# STM32C092xx register map
File version: 1.0
Registers are 32-bit, read-write, reset 0x0 unless marked. A register's access mark holds for its fields unless they carry their own. Offsets are from the block's base; [hi:lo] are bit positions; {n}, {i} and the like mark numbered series; 'fields as' and 'values as' point back to an identical list.

## FDCAN_CONFIG — FD Controller Area Network Configuration
Base 0x40006500
0x00 CKDIV — FDCAN clock divider register
  [3:0] PDIV — Input Clock Divider

## PWR — Power Control
Base 0x40007000
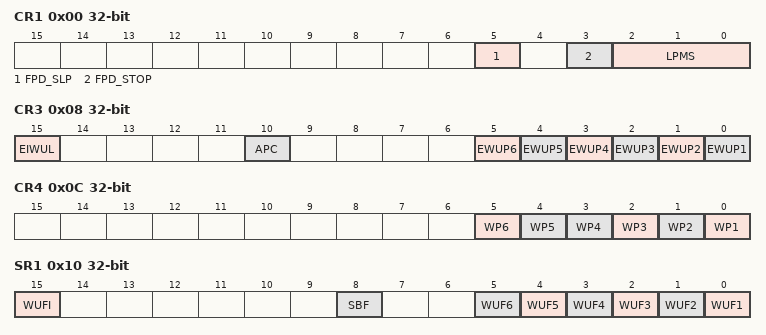
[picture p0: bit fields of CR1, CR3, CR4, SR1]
0x00 CR1 — PWR Power Control Register 1
  [5] FPD_SLP — Flash power down mode during sleep
  [3] FPD_STOP — Flash power down mode during stop
  [2:0] LPMS — Low Power Mode Selection
    0=STOP0; 3=STANDBY; 4=SHUTDOWN
0x08 CR3 — PWR Power Control Register 3
  [15] EIWUL — Enable Internal Wake-up line
  [10] APC — Apply pull-up and pull-down configuration
  [5] EWUP6 — Enable external WKUP pin 6
  [4] EWUP5 — Enable WKUP pin 5
  [3] EWUP4 — Enable external WKUP pin 4
  [2] EWUP3 — Enable external WKUP pin 3
  [1] EWUP2 — Enable external WKUP pin 2
  [0] EWUP1 — Enable external WKUP Line 1
0x0C CR4 — PWR Power Control Register 4
  [5] WP6 — Wake-Up Line 6 polarity
  [4] WP5 — Wake-Up Pin 5 polarity
  [n-1] WP{n} (n=1..4) — Wake-Up Line {n} polarity
0x10 SR1 — PWR Power Status Register 1
  [15] WUFI — Wakeup Flag Internal
  [8] SBF — Standby Flag
  [n-1] WUF{n} (n=1..6) — Wakeup Flag {n}
0x14 SR2 — PWR Power Status Register 2
  [7] FLASH_RDY — Flash Ready
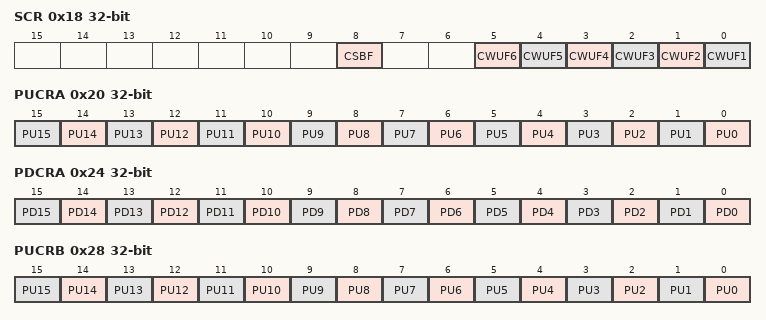
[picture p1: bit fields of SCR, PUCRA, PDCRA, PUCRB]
0x18 SCR — PWR Power Status Clear Register
  [8] CSBF — Clear Standby Flag
  [n-1] CWUF{n} (n=1..6) — Clear Wake-up Flag {n}
0x20 PUCRA — PWR Pull-Up Control Register of port A
  [n] PU{n} (n=0..15) — Pin PA{n} Pull-Up set
0x24 PDCRA — PWR Pull-Down Control Register of port A
  [n] PD{n} (n=0..15) — Pin PA{n} Pull-Down set
0x28 PUCRB — PWR Pull-Up Control Register of port B
  [n] PU{n} (n=0..15) — Pin PB{n} Pull-Up set
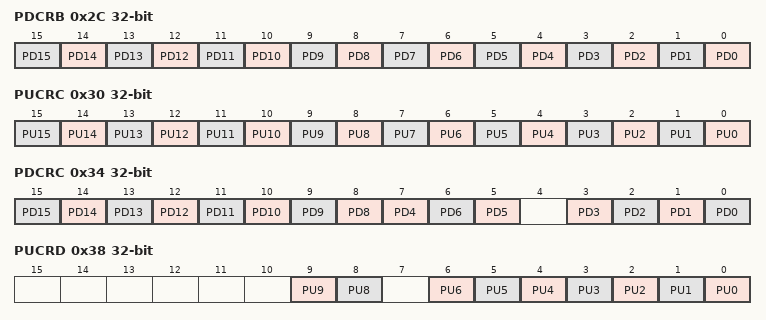
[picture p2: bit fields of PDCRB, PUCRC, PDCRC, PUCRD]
0x2C PDCRB — PWR Pull-Down Control Register of port B
  [n] PD{n} (n=0..15) — Pin PB{n} Pull-Down set
0x30 PUCRC — PWR Pull-Up Control Register of port C
  [n] PU{n} (n=0..15) — Pin PC{n} Pull-Up set
0x34 PDCRC — PWR Pull-Down Control Register of port C
  [n] PD{n} (n=8..15) — Pin PC{n} Pull-Down set
  [7] PD4 — Pin PC4 Pull-Down set
  [6] PD6 — Pin PC6 Pull-Down set
  [5] PD5 — Pin PC5 Pull-Down set
  [n] PD{n} (n=0..3) — Pin PC{n} Pull-Down set
0x38 PUCRD — PWR Pull-Up Control Register of port D
  [9] PU9 — Pin PD9 Pull-Up set
  [8] PU8 — Pin PD8 Pull-Up set
  [n] PU{n} (n=0..6) — Pin PD{n} Pull-Up set
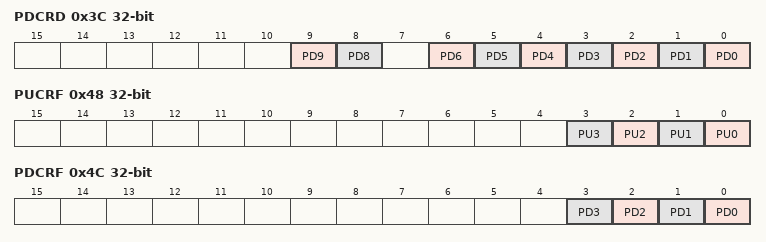
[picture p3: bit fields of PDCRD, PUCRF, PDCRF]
0x3C PDCRD — PWR Pull-Down Control Register of port D
  [9] PD9 — Pin PD9 Pull-Down set
  [8] PD8 — Pin PD8 Pull-Down set
  [n] PD{n} (n=0..6) — Pin PD{n} Pull-Down set
0x48 PUCRF — PWR Pull-Up Control Register of port F
  [n] PU{n} (n=0..3) — Pin PF{n} Pull-Up set
0x4C PDCRF — PWR Pull-Down Control Register of port F
  [n] PD{n} (n=0..3) — Pin PF{n} Pull-Down set
{0x70+4i} BKP{i}R (i=0..3) — Backup register {i}

## DBG — Debug MCU
Base 0x40015800
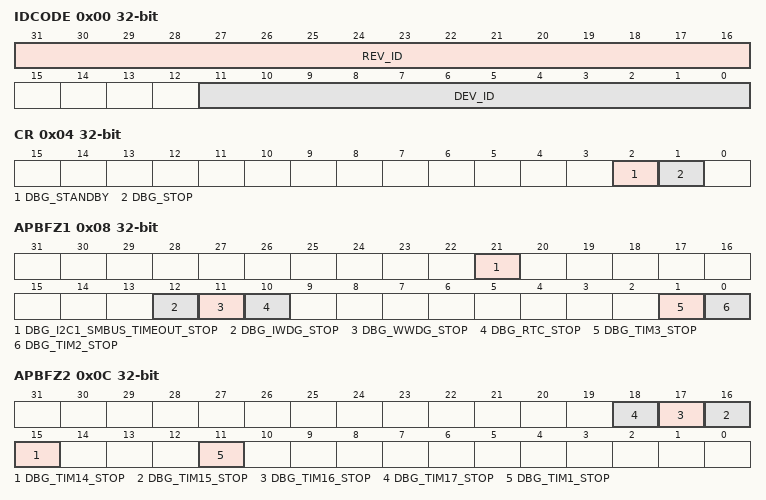
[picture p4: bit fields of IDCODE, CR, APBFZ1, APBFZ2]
0x00 IDCODE — MCU device ID code
  [31:16] REV_ID, [11:0] DEV_ID
0x04 CR — Debug configuration register
  [2] DBG_STANDBY, [1] DBG_STOP
0x08 APBFZ1 — Debug APB freeze register 1
  [21] DBG_I2C1_SMBUS_TIMEOUT_STOP, [12] DBG_IWDG_STOP, [11] DBG_WWDG_STOP, [10] DBG_RTC_STOP, [1] DBG_TIM3_STOP, [0] DBG_TIM2_STOP
0x0C APBFZ2 — Debug APB freeze register 2
  [n+1] DBG_TIM{n}_STOP (n=14..17), [11] DBG_TIM1_STOP

## DMA1
Base 0x40020000
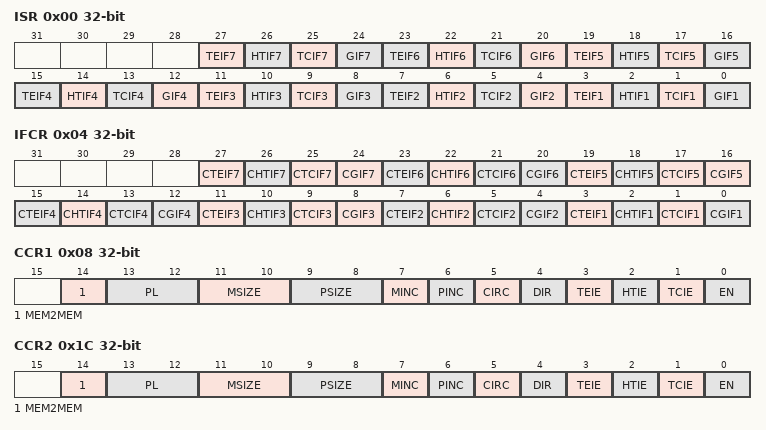
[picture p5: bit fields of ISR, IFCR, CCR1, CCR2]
0x00 ISR — DMA interrupt status register
  [4n-1] TEIF{n} (n=1..7) — Channel {n} Transfer Error flag
  [4n-2] HTIF{n} (n=1..7) — Channel {n} Half Transfer flag
  [25] TCIF7 — Channel 7Transfer Complete flag
  [4n-4] GIF{n} (n=1..7) — Channel {n} Global interrupt flag
  [4n-3] TCIF{n} (n=1..6) — Channel {n} Transfer Complete flag
0x04 IFCR — DMA interrupt flag clear register
  [4n-1] CTEIF{n} (n=1..7) — Channel {n} Transfer Error clear
  [4n-2] CHTIF{n} (n=1..7) — Channel {n} Half Transfer clear
  [4n-3] CTCIF{n} (n=1..7) — Channel {n} Transfer Complete clear
  [4n-4] CGIF{n} (n=2..7) — Channel {n} Global interrupt clear
  [0] CGIF1 — Channel 1 Global interrupt clearr
0x08 CCR1 — DMA channel x configuration register
  [14] MEM2MEM — Memory to memory mode
  [13:12] PL — PL[1:0] bits(Channel Priority level)
  [11:10] MSIZE — MSIZE[1:0] bits (Memory size)
  [9:8] PSIZE — PSIZE[1:0] bits (Peripheral size)
  [7] MINC — Memory increment mode
  [6] PINC — Peripheral increment mode
  [5] CIRC — Circular mode
  [4] DIR — Data transfer direction
  [3] TEIE — Transfer error interrupt enable
  [2] HTIE — Half Transfer interrupt enable
  [1] TCIE — Transfer complete interrupt enable
  [0] EN — Channel enable
0x0C CNDTR1 — DMA channel x number of data register
  [15:0] NDT — Number of data to Transfer
0x10 CPAR1 — DMA channel x peripheral address register
  [31:0] PA — Peripheral Address
{0x0+0x14*i} CMAR{i} (i=1..7) — DMA channel x memory address register
  [31:0] MA — Memory Address
0x1C CCR2 — DMA channel x configuration register
  fields as CCR1
0x20 CNDTR2 — DMA channel x number of data register
  [15:0] NDT — Number of data to Transfer
0x24 CPAR2 — DMA channel x peripheral address register
  [31:0] PA — Peripheral Address
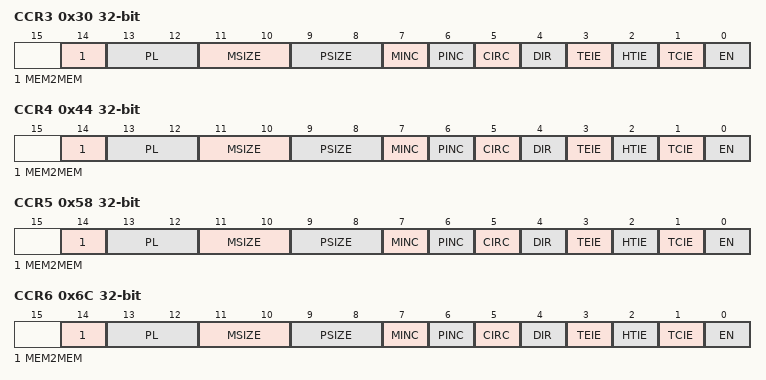
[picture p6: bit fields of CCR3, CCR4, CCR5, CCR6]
0x30 CCR3 — DMA channel x configuration register
  fields as CCR1
0x34 CNDTR3 — DMA channel x number of data register
  [15:0] NDT — Number of data to Transfer
0x38 CPAR3 — DMA channel x peripheral address register
  [31:0] PA — Peripheral Address
0x44 CCR4 — DMA channel x configuration register
  fields as CCR1
0x48 CNDTR4 — DMA channel x number of data register
  [15:0] NDT — Number of data to Transfer
0x4C CPAR4 — DMA channel x peripheral address register
  [31:0] PA — Peripheral Address
0x58 CCR5 — DMA channel x configuration register
  fields as CCR1
0x5C CNDTR5 — DMA channel x number of data register
  [15:0] NDT — Number of data to Transfer
0x60 CPAR5 — DMA channel x peripheral address register
  [31:0] PA — Peripheral Address
0x6C CCR6 — DMA channel x configuration register
  fields as CCR1
0x70 CNDTR6 — DMA channel x number of data register
  [15:0] NDT — Number of data to Transfer
0x74 CPAR6 — DMA channel x peripheral address register
  [31:0] PA — Peripheral Address
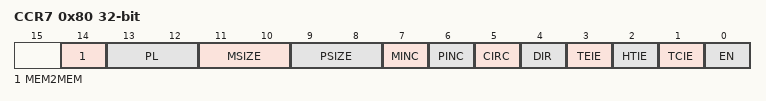
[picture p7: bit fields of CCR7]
0x80 CCR7 — DMA channel x configuration register
  fields as CCR1
0x84 CNDTR7 — DMA channel x number of data register
  [15:0] NDT — Number of data to Transfer
0x88 CPAR7 — DMA channel x peripheral address register
  [31:0] PA — Peripheral Address
